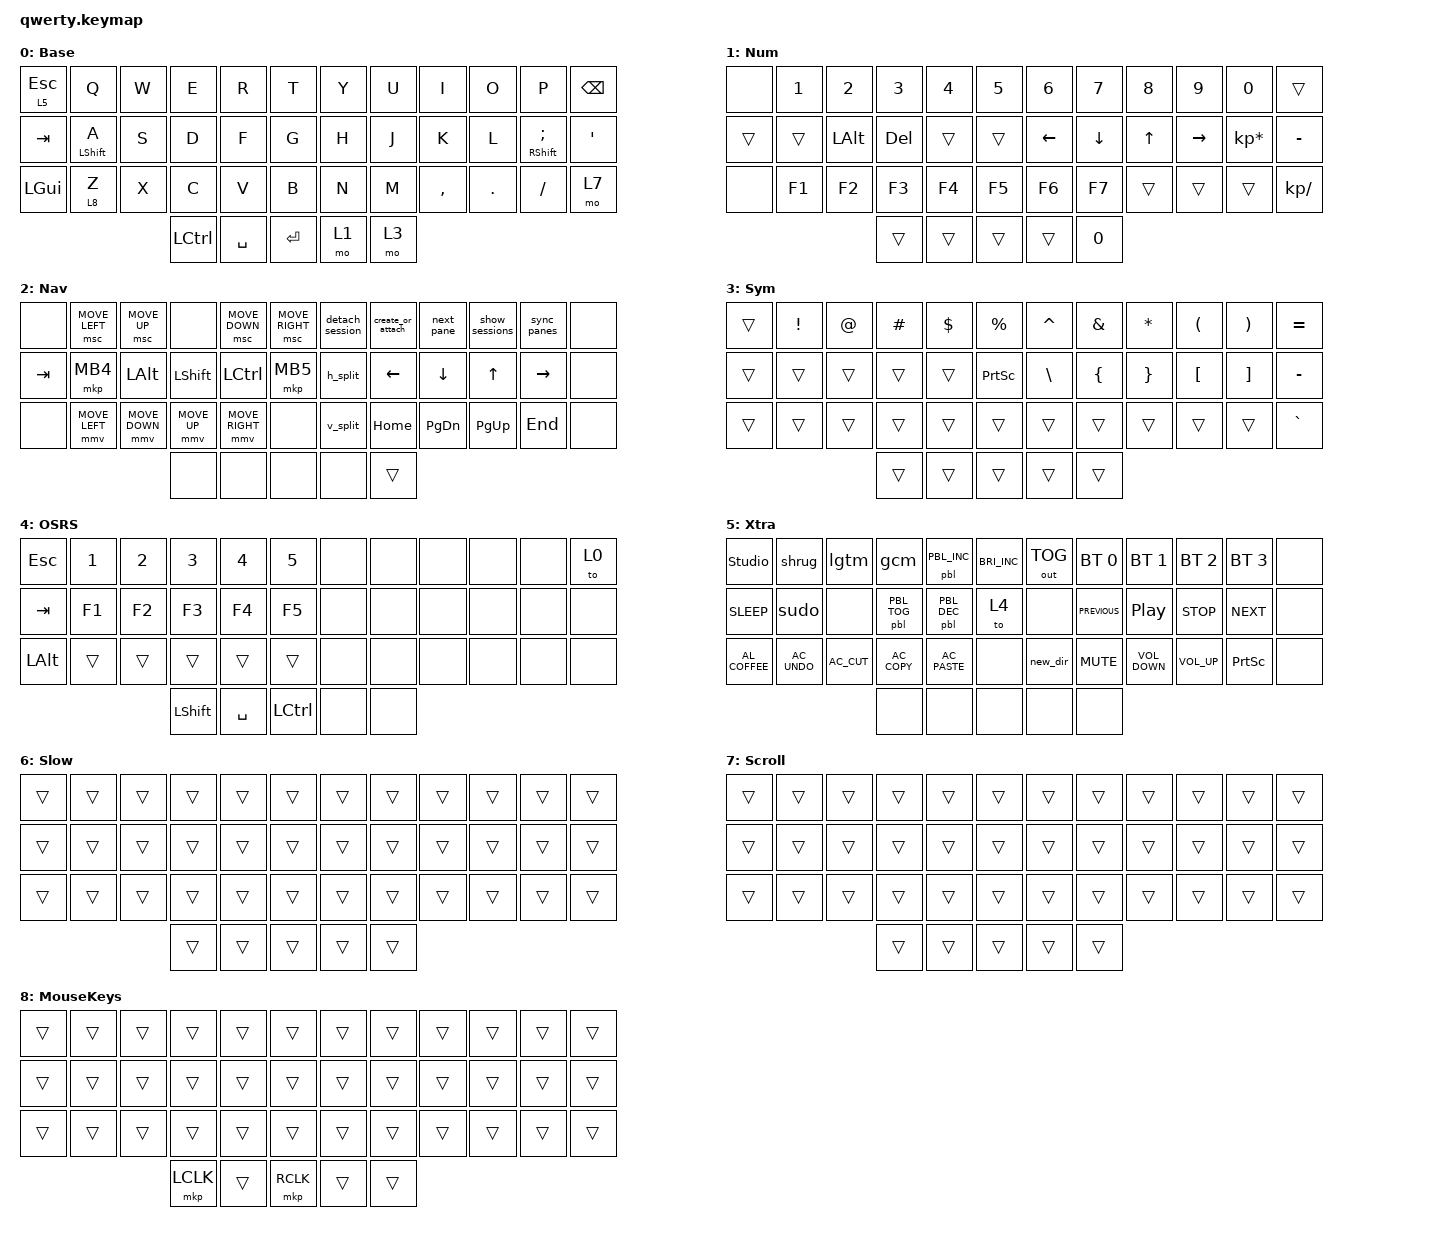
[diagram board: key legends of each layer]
/* upstream bindings and behaviors */

#include <dt-bindings/zmk/mouse.h>
#include <behaviors/mouse_keys.dtsi>
#include <behaviors.dtsi>
#include <dt-bindings/zmk/bt.h>
#include <dt-bindings/zmk/keys.h>
#include <dt-bindings/zmk/outputs.h>
#include <dt-bindings/zmk/pointing.h>

/* local overlays */

#include "keymap_features/prospector_brightness.dtsi"
#include "keymap_features/macros.dtsi"
#include "keymap_features/behaviors.dtsi"
#include "keymap_features/combos.dtsi"

/ {
    /* --- KEYMAP CONFIG --- */
    // ╭──────┬──────┬──────┬──────┬──────┬──────╮  ╭──────┬──────┬──────┬──────┬──────┬──────╮
    //    00     01     02     03    04      05        06     07     08     09     10     11
    // ├──────┼──────┼──────┼──────┼──────┼──────┤  ├──────┼──────┼──────┼──────┼──────┼──────┤
    //    12     13     14     15    16      17        18     19     20     21     22     23
    // ├──────┼──────┼──────┼──────┼──────┼──────┤  ├──────┼──────┼──────┼──────┼──────┼──────┤
    //    24     25     26     27    28      29        30     31     32     33     34     35
    // ╰──────┴──────┴──────┼──────┼──────┼──────┤  ├──────┼──────┼──────┴──────┴──────┴──────╯
    //                         36     37     38        39     40
    //                      ╰──────┴──────┴──────╯  ╰──────┴──────╯
    // #define BASE    0
    // #define NUM     1
    // #define NAV     2
    // #define SYM     3
    // #define GAME    4
    // #define EXTRAS  5
    // #define SLOW    6
    // #define SCROLL  7
    // This shared keymap builds for prospector and non-prospector firmwares. 
    // This stubs the key bindings that are contained in the prospector module
    // so non-prospector firmware can build.

    #ifndef CONFIG_SHIELD_PROSPECTOR_ADAPTER

    behaviors {
        /omit-if-no-ref/

        pbl: prospector_brightness_stub {
            compatible = "zmk,behavior-macro-two-param";
            #binding-cells = <2>;
            bindings = <&none>;
        };

        hm: hm {
            compatible = "zmk,behavior-hold-tap";
            label = "HM";
            bindings = <&kp>, <&kp>;

            #binding-cells = <2>;
            tapping-term-ms = <260>;
            quick-tap-ms = <220>;
            require-prior-idle-ms = <185>;
            flavor = "balanced";
        };

        layer_key: layer_key {
            compatible = "zmk,behavior-hold-tap";
            label = "LAYER_KEY";
            bindings = <&mo>, <&kp>;

            #binding-cells = <2>;
            tapping-term-ms = <260>;
            quick-tap-ms = <220>;
            require-prior-idle-ms = <185>;
            flavor = "balanced";
        };
    };

    #endif

    macros {
    };

    keymap {
        compatible = "zmk,keymap";

        BASE {
            display-name = "Base";
            bindings = <
&lt 5 ESCAPE  &kp Q             &kp W  &kp E      &kp R      &kp T        &kp Y  &kp U  &kp I      &kp O       &kp P                      &kp BACKSPACE
&kp TAB       &hm LEFT_SHIFT A  &kp S  &kp D      &kp F      &kp G        &kp H  &kp J  &kp K      &kp L       &hm RIGHT_SHIFT SEMICOLON  &kp SQT
&kp LEFT_GUI  &layer_key 8 Z    &kp X  &kp C      &kp V      &kp B        &kp N  &kp M  &kp COMMA  &kp PERIOD  &kp SLASH                  &mo 7
                                       &kp LCTRL  &kp SPACE  &kp ENTER    &mo 1  &mo 3
            >;
        };

        NUM {
            display-name = "Num";
            bindings = <
&none   &kp NUMBER_1  &kp NUMBER_2  &kp NUMBER_3  &kp NUMBER_4  &kp N5    &kp NUMBER_6    &kp N7    &kp N8        &kp N9     &kp N0           &trans
&trans  &trans        &kp LEFT_ALT  &kp DEL       &trans        &trans    &kp LEFT_ARROW  &kp DOWN  &kp UP_ARROW  &kp RIGHT  &kp KP_MULTIPLY  &kp MINUS
&none   &kp F1        &kp F2        &kp F3        &kp F4        &kp F5    &kp F6          &kp F7    &trans        &trans     &trans           &kp KP_SLASH
                                    &trans        &trans        &trans    &trans          &kp N0
            >;
        };

        NAV {
            display-name = "Nav";
            bindings = <
&none    &msc MOVE_LEFT  &msc MOVE_UP    &none         &msc MOVE_DOWN   &msc MOVE_RIGHT    &detach_session  &create_or_attach  &next_pane  &show_sessions  &sync_panes      &none
&kp TAB  &mkp MB4        &kp LALT        &kp LSHFT     &kp LCTRL        &mkp MB5           &h_split         &kp LEFT_ARROW     &kp DOWN    &kp UP          &kp RIGHT_ARROW  &none
&none    &mmv MOVE_LEFT  &mmv MOVE_DOWN  &mmv MOVE_UP  &mmv MOVE_RIGHT  &none              &v_split         &kp HOME           &kp PG_DN   &kp PG_UP       &kp END          &none
                                         &none         &none            &none              &none            &trans
            >;
        };

        SYM {
            display-name = "Sym";
            bindings = <
&trans  &kp EXCLAMATION  &kp AT_SIGN  &kp HASH  &kp DOLLAR  &kp PERCENT        &kp CARET      &kp AMPERSAND   &kp ASTERISK     &kp LEFT_PARENTHESIS  &kp RIGHT_PARENTHESIS  &kp EQUAL
&trans  &trans           &trans       &trans    &trans      &kp PRINTSCREEN    &kp BACKSLASH  &kp LEFT_BRACE  &kp RIGHT_BRACE  &kp LEFT_BRACKET      &kp RIGHT_BRACKET      &kp MINUS
&trans  &trans           &trans       &trans    &trans      &trans             &trans         &trans          &trans           &trans                &trans                 &kp GRAVE
                                      &trans    &trans      &trans             &trans         &trans
            >;
        };

        OSRS {
            display-name = "OSRS";
            bindings = <
&kp ESCAPE    &kp NUMBER_1  &kp NUMBER_2  &kp NUMBER_3    &kp N4     &kp N5       &none  &none  &none  &none  &none  &to 0
&kp TAB       &kp F1        &kp F2        &kp F3          &kp F4     &kp F5       &none  &none  &none  &none  &none  &none
&kp LEFT_ALT  &trans        &trans        &trans          &trans     &trans       &none  &none  &none  &none  &none  &none
                                          &kp LEFT_SHIFT  &kp SPACE  &kp LCTRL    &none  &none
            >;
        };

        EXTRAS {
            display-name = "Xtra";
            bindings = <
&studio_unlock   &shrug         &lgtm         &gcm           &pbl PBL_INC    &kp C_BRIGHTNESS_INC    &out OUT_TOG  &bt BT_SEL 0    &bt BT_SEL 1       &bt BT_SEL 2     &bt BT_SEL 3     &none
&kp C_SLEEP      &sudo          &none         &pbl PBL_TOG   &pbl PBL_DEC    &to 4                   &none         &kp C_PREVIOUS  &kp C_PLAY_PAUSE   &kp C_STOP       &kp C_NEXT       &none
&kp C_AL_COFFEE  &kp C_AC_UNDO  &kp C_AC_CUT  &kp C_AC_COPY  &kp C_AC_PASTE  &none                   &new_dir      &kp K_MUTE      &kp C_VOLUME_DOWN  &kp C_VOLUME_UP  &kp PRINTSCREEN  &none
                                              &none          &none           &none                   &none         &none
            >;
        };

        SLOW {
            display-name = "Slow";
            bindings = <
&trans  &trans  &trans  &trans  &trans  &trans    &trans  &trans  &trans  &trans  &trans  &trans
&trans  &trans  &trans  &trans  &trans  &trans    &trans  &trans  &trans  &trans  &trans  &trans
&trans  &trans  &trans  &trans  &trans  &trans    &trans  &trans  &trans  &trans  &trans  &trans
                        &trans  &trans  &trans    &trans  &trans
            >;
        };

        SCROLL {
            display-name = "Scroll";
            bindings = <
&trans  &trans  &trans  &trans  &trans  &trans    &trans  &trans  &trans  &trans  &trans  &trans
&trans  &trans  &trans  &trans  &trans  &trans    &trans  &trans  &trans  &trans  &trans  &trans
&trans  &trans  &trans  &trans  &trans  &trans    &trans  &trans  &trans  &trans  &trans  &trans
                        &trans  &trans  &trans    &trans  &trans
            >;
        };

        MouseKeys {
            bindings = <
&trans  &trans  &trans  &trans     &trans  &trans       &trans  &trans  &trans  &trans  &trans  &trans
&trans  &trans  &trans  &trans     &trans  &trans       &trans  &trans  &trans  &trans  &trans  &trans
&trans  &trans  &trans  &trans     &trans  &trans       &trans  &trans  &trans  &trans  &trans  &trans
                        &mkp LCLK  &trans  &mkp RCLK    &trans  &trans
            >;
        };
    };
};
